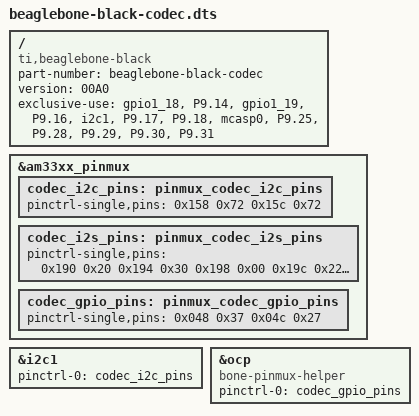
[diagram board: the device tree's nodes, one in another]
/dts-v1/;
/plugin/; /* Allow undefined label references and record them */

/ {
    compatible = "ti,beaglebone-black";

    /* Identification */
    part-number = "beaglebone-black-codec";
    version = "00A0";

    /* State the resources this cape uses */
    exclusive-use =
        "gpio1_18",
        "P9.14", /* cs4272_rst */
        "gpio1_19",
        "P9.16", /* cs4272_ad0 */
        "i2c1",
        "P9.17", /* i2c1_scl */
        "P9.18", /* i2c1_sda */
        "mcasp0",
        "P9.25", /* mcasp0_ahclkx */
        "P9.28", /* mcasp0_axr2 */
        "P9.29", /* mcasp0_fsx */
        "P9.30", /* mcasp0_axr0 */
        "P9.31"; /* mcasp0_aclkx */

    /* Documentation: https://www.kernel.org/doc/Documentation/devicetree/bindings/pinctrl/pinctrl-single.txt */
    fragment@0 {
        target = <&am33xx_pinmux>;

        __overlay__ {
            codec_i2c_pins: pinmux_codec_i2c_pins {
                pinctrl-single,pins = <
					0x158 0x72 /* i2c1_sda: slew control slow, input, pull up, mode 2 */
					0x15c 0x72 /* i2c1_scl: slew control slow, input, pull up, mode 2 */
                >;
            };

            codec_i2s_pins: pinmux_codec_i2s_pins {
                pinctrl-single,pins = <
                    0x190 0x20 /* mcasp0_aclkx:  output, pull down, mode 0 */
                    0x194 0x30 /* mcasp0_fsx:    output, pull up,   mode 0 */
                    0x198 0x00 /* mcasp0_axr0:   input,  pull down, mode 0 */
                    0x19c 0x22 /* mcasp0_axr2:   output, pull down, mode 2 */
                    0x1ac 0x10 /* mcasp0_ahclkx: input,  pull up,   mode 0 */
                >;
            };


            codec_gpio_pins: pinmux_codec_gpio_pins {
                pinctrl-single,pins = <
                    0x048 0x37 /* cs4272_rst: output, pull up,   mode 7 */
                    0x04c 0x27 /* cs4272_ad0: output, pull down, mode 7 */
                >;
            };
        };
    };

    /* Documentation: https://www.kernel.org/doc/Documentation/devicetree/bindings/i2c/i2c.txt */
    fragment@1 {
		target = <&i2c1>;

		__overlay__ {
			status = "okay";

			pinctrl-names = "default";
			pinctrl-0 = <&codec_i2c_pins>;
		};
    };

    fragment@2 {
        target = <&ocp>;

        __overlay__ {
            status = "okay";

            pinctrl-names = "default";
            pinctrl-0 = <&codec_gpio_pins>;

            compatible = "bone-pinmux-helper";
        };
    };
};
